# M471 register map
File version: 1.0
Registers are 32-bit, read-write, reset 0x0 unless marked. A register's access mark holds for its fields unless they carry their own. Offsets are from the block's base; [hi:lo] are bit positions; {n}, {i} and the like mark numbered series; 'fields as' and 'values as' point back to an identical list.

## SYS — SYS Register Map
Base 0x40000000
0x00 SYS_PDID ro reset 0x1647140 — Part Device Identification Number Register
  [31:0] PDID — Part Device Identification Number (Read Only). This register reflects device part number code. Software can read this register to identify which device is used. Note: After chip power-on, this bit is defined by ROMMAP2[31:0]
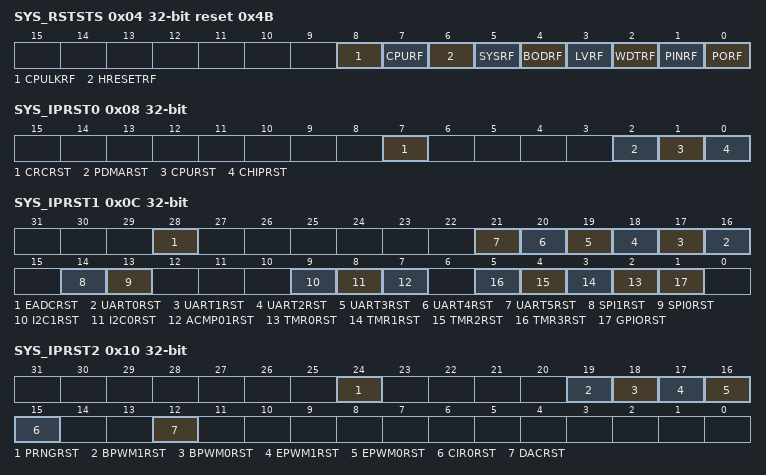
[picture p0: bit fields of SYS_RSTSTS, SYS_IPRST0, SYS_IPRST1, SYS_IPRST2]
0x04 SYS_RSTSTS reset 0x4B — System Reset Status Register
  [8] CPULKRF — CPU Lockup Reset Flag. Note 1: Write 1 to clear this bit to 0. Note 2: When CPU lockup happened under ICE is connected, this flag will set to 1 but chip will not reset.
    0=No reset from CPU lockup happened; 1=The Cortex-M4 lockup happened and chip is reset
  [7] CPURF — CPU Reset Flag. The CPU reset flag is set by hardware if software writes CPURST (SYS_IPRST0[1]) 1 to reset Cortex-M4 Core and Flash Memory Controller (FMC). Note: Write 1 to clear this bit to 0.
    0=No reset from CPU; 1=The Cortex-M4 Core and FMC are reset by software setting CPURST to 1
  [6] HRESETRF — HRESET Reset Flag. The HRESET reset flag is set by the 'Reset Signal' from the HRESET. Note: Write 1 to clear this bit to 0.
    0=No reset from HRESET; 1=Reset from HRESET
  [5] SYSRF — System Reset Flag. The system reset flag is set by the 'Reset Signal' from the Cortex-M4 Core to indicate the previous reset source. Note: Write 1 to clear this bit to 0.
    0=No reset from Cortex-M4; 1=The Cortex-M4 had issued the reset signal to reset the system by writing 1 to the bit SYSRESETREQ(AIRCR[2], Application Interrupt and Reset Control Register, address = 0xE000ED0C) in system control registers of Cortex-M4 core
  [4] BODRF — BOD Reset Flag. The BOD reset flag is set by the 'Reset Signal' from the Brown-Out Detector to indicate the previous reset source. Note: Write 1 to clear this bit to 0.
    0=No reset from BOD; 1=The BOD had issued the reset signal to reset the system
  [3] LVRF — LVR Reset Flag. The LVR reset flag is set by the 'Reset Signal' from the Low Voltage Reset Controller to indicate the previous reset source. Note: Write 1 to clear this bit to 0.
    0=No reset from LVR; 1=LVR controller had issued the reset signal to reset the system
  [2] WDTRF — WDT Reset Flag. The WDT reset flag is set by the 'Reset Signal' from the Watchdog Timer or Window Watchdog Timer to indicate the previous reset source. Note 1: Write 1 to clear this bit to 0. Note 2: Watchdog Timer register RSTF(WDT_CTL[2]) bit is set if the system has been reset by WDT time-out reset. Window Watchdog Timer register WWDTRF(WWDT_STATUS[1]) bit is set if the system has been reset by WWDT time-out reset.
    0=No reset from watchdog timer or window watchdog timer; 1=The watchdog timer or window watchdog timer had issued the reset signal to reset the system
  [1] PINRF — NRESET Pin Reset Flag. The nRESET pin reset flag is set by the 'Reset Signal' from the nRESET Pin to indicate the previous reset source. Note: Write 1 to clear this bit to 0.
    0=No reset from nRESET pin; 1=Pin nRESET had issued the reset signal to reset the system
  [0] PORF — POR Reset Flag. The POR reset flag is set by the 'Reset Signal' from the Power-on Reset (POR) Controller or bit CHIPRST (SYS_IPRST0[0]) to indicate the previous reset source. Note: Write 1 to clear this bit to 0.
    0=No reset from POR or CHIPRST; 1=Power-on Reset (POR) or CHIPRST had issued the reset signal to reset the system
0x08 SYS_IPRST0 — Peripheral Reset Control Register 0
  [7] CRCRST — CRC Calculation Controller Reset (Write Protect). Set this bit to 1 will generate a reset signal to the CRC calculation controller. User needs to set this bit to 0 to release from the reset state. Note: This bit is write protected. Refer to the SYS_REGLCTL register.
    0=CRC calculation controller normal operation; 1=CRC calculation controller reset
  [2] PDMARST — PDMA Controller Reset (Write Protect). Setting this bit to 1 will generate a reset signal to the PDMA. User needs to set this bit to 0 to release from reset state. Note: This bit is write protected. Refer to the SYS_REGLCTL register.
    0=PDMA controller normal operation; 1=PDMA controller reset
  [1] CPURST — Processor Core One-shot Reset (Write Protect). Setting this bit will only reset the processor core and Flash Memory Controller(FMC), and this bit will automatically return to 0 after the 2 clock cycles. Note: This bit is write protected. Refer to the SYS_REGLCTL register.
    0=Processor core normal operation; 1=Processor core one-shot reset
  [0] CHIPRST — Chip One-shot Reset (Write Protect). Setting this bit will reset the whole chip, including Processor core and all peripherals, and this bit will automatically return to 0 after the 2 clock cycles. The CHIPRST is same as the POR reset, all the chip controllers is reset and the chip setting from Flash are also reload. About the difference between CHIPRST and SYSRESETREQ(AIRCR[2]), please refer to section 7.2.2. Note: This bit is write protected. Refer to the SYS_REGLCTL register.
    0=Chip normal operation; 1=Chip one-shot reset
0x0C SYS_IPRST1 — Peripheral Reset Control Register 1
  [28] EADCRST — EADC Controller Reset
    0=EADC controller normal operation; 1=EADC controller reset
  [n+16] UART{n}RST (n=0..5) — UART{n} Controller Reset
    0=UART{n} controller normal operation; 1=UART{n} controller reset
  [14] SPI1RST — SPI1 Controller Reset
    0=SPI1 controller normal operation; 1=SPI1 controller reset
  [13] SPI0RST — SPI0 Controller Reset
    0=SPI0 controller normal operation; 1=SPI0 controller reset
  [9] I2C1RST — I2C1 Controller Reset
    0=I2C1 controller normal operation; 1=I2C1 controller reset
  [8] I2C0RST — I2C0 Controller Reset
    0=I2C0 controller normal operation; 1=I2C0 controller reset
  [7] ACMP01RST — Analog Comparator 0/1 Controller Reset
    0=Analog Comparator 0/1 controller normal operation; 1=Analog Comparator 0/1 controller reset
  [n+2] TMR{n}RST (n=0..3) — Timer{n} Controller Reset
    0=Timer{n} controller normal operation; 1=Timer{n} controller reset
  [1] GPIORST — GPIO Controller Reset
    0=GPIO controller normal operation; 1=GPIO controller reset
0x10 SYS_IPRST2 — Peripheral Reset Control Register 2
  [24] PRNGRST — PRNG Controller Reset
    0=PRNG controller normal operation; 1=PRNG controller reset
  [19] BPWM1RST — BPWM1 Controller Reset
    0=BPWM1 controller normal operation; 1=BPWM1 controller reset
  [18] BPWM0RST — BPWM0 Controller Reset
    0=BPWM0 controller normal operation; 1=BPWM0 controller reset
  [17] EPWM1RST — EPWM1 Controller Reset
    0=EPWM1 controller normal operation; 1=EPWM1 controller reset
  [16] EPWM0RST — EPWM0 Controller Reset
    0=EPWM0 controller normal operation; 1=EPWM0 controller reset
  [15] CIR0RST — CIR0 Controller Reset
    0=CIR0 controller normal operation; 1=CIR0 controller reset
  [12] DACRST — DAC Controller Reset
    0=DAC controller normal operation; 1=DAC controller reset
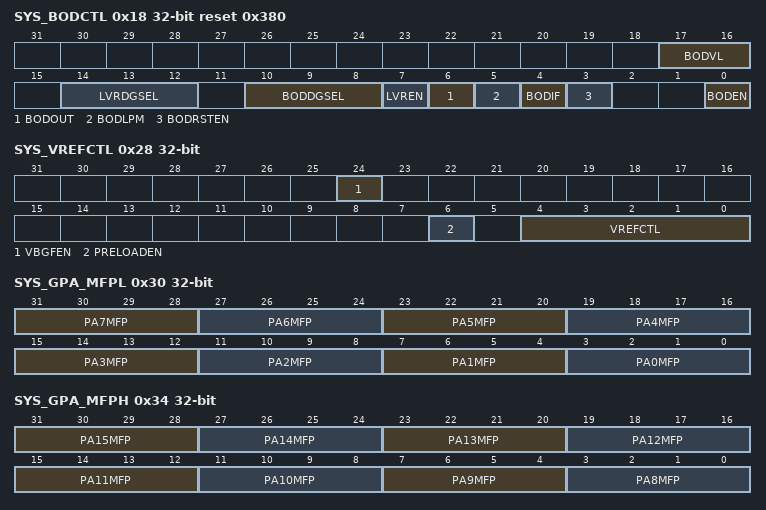
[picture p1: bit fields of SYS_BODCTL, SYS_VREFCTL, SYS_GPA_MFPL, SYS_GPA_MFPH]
0x18 SYS_BODCTL reset 0x380 (reset mask 0xFFF0FFF0) — Brown-out Detector Control Register
  [17:16] BODVL — Brown-out Detector Threshold Voltage Selection (Write Protect). The default value is set by Flash controller user configuration register CBOV (CONFIG0 [22:21]). Note: This bit is write protected. Refer to the SYS_REGLCTL register.
    0=Brown-Out Detector threshold voltage is 2.4V; 1=Brown-Out Detector threshold voltage is 2.7V; 2=Brown-Out Detector threshold voltage is 3.7V; 3=Brown-Out Detector threshold voltage is 4.4V
  [14:12] LVRDGSEL — LVR Output De-glitch Time Select (Write Protect). Note: These bits are write protected. Refer to the SYS_REGLCTL register.
    0=Without de-glitch function; 1=4 system clock (HCLK); 2=8 system clock (HCLK); 3=16 system clock (HCLK); 4=32 system clock (HCLK); 5=64 system clock (HCLK); 6=128 system clock (HCLK); 7=256 system clock (HCLK)
  [10:8] BODDGSEL — Brown-out Detector Output De-glitch Time Select (Write Protect). Note: These bits are write protected. Refer to the SYS_REGLCTL register.
    0=BOD output is sampled by RC10K clock; 1=4 system clock (HCLK); 2=8 system clock (HCLK); 3=16 system clock (HCLK); 4=32 system clock (HCLK); 5=64 system clock (HCLK); 6=128 system clock (HCLK); 7=256 system clock (HCLK)
  [7] LVREN — Low Voltage Reset Enable Bit (Write Protect). The LVR function resets the chip when the input power voltage is lower than LVR circuit setting. LVR function is enabled by default. Note 1: After enabling the bit, the LVR function will be active with 100us delay for LVR output stable (default). Note 2: This bit is write protected. Refer to the SYS_REGLCTL register.
    0=Low Voltage Reset function Disabled; 1=Low Voltage Reset function Enabled
  [6] BODOUT — Brown-out Detector Output Status. It means the detected voltage is lower than BODVL setting. If the BODEN is 0, BOD function disabled, this bit always responds 0.
    0=Brown-out Detector output status is 0; 1=Brown-out Detector output status is 1
  [5] BODLPM — Brown-out Detector Low Power Mode (Write Protect). Note 1: The BOD consumes about 100uA in normal mode, the low power mode can reduce the current to about 1/10 but slow the BOD response. Note 2: This bit is write protected. Refer to the SYS_REGLCTL register. Note 3:BOD enable stable time is 50us, period enable time need larger than it
    0=BOD operate in normal mode (default); 1=BOD Low Power mode Enabled
  [4] BODIF — Brown-out Detector Interrupt Flag. Note: Write 1 to clear this bit to 0.
    0=Brown-out Detector does not detect any voltage draft at VDD down through or up through the voltage of BODVL setting; 1=When Brown-out Detector detects the VDD is dropped down through the voltage of BODVL setting or the VDD is raised up through the voltage of BODVL setting, this bit is set to 1 and the brown-out interrupt is requested if brown-out interrupt is enabled
  [3] BODRSTEN — Brown-out Reset Enable Bit (Write Protect). The default value is set by Flash controller user configuration register CBORST(CONFIG0[20]) bit. Note 1: While the Brown-out Detector function is enabled (BODEN high) and BOD reset function is enabled (BODRSTEN high), BOD will assert a signal to reset chip when the detected voltage is lower than the threshold (BODOUT high). While the BOD function is enabled (BODEN high) and BOD interrupt function is enabled (BODRSTEN low), BOD will assert an interrupt if BODOUT is high. BOD interrupt will be kept till to the BODEN is set to 0. BOD interrupt can be blocked by disabling the NVIC BOD interrupt or disabling BOD function (set BODEN low). Note 2: This bit is write protected. Refer to the SYS_REGLCTL register.
    0=Brown-out 'INTERRUPT' function Enabled; 1=Brown-out 'RESET' function Enabled
  [0] BODEN — Brown-out Detector Enable Bit (Write Protect). The default value is set by Flash controller user configuration register CBODEN (CONFIG0 [19]). Note: This bit is write protected. Refer to the SYS_REGLCTL register.
    0=Brown-out Detector function Disabled; 1=Brown-out Detector function Enabled
0x1C SYS_IVSCTL — Internal Voltage Source Control Register
  [0] VTEMPEN — Temperature Sensor Enable Bit. This bit is used to enable/disable temperature sensor function.
    0=Temperature sensor function Disabled (default); 1=Temperature sensor function Enabled
0x28 SYS_VREFCTL — VREF Control Register
  [24] VBGFEN wo — Chip Internal Voltage Band-gap Force Enable Bit(Write Only). Note: If user want to read the value of this bit, please read bit[25].
    0=Chip internal voltage band-gap controlled by ADC/ACMP if source selected; 1=Chip internal voltage band-gap force enable
  [6] PRELOADEN — Pre-load Function Enable Bit (Write Protect). This bit should be enabled and keep during Tstable when VREFCTL(SYS_VREFCTL[4:0]) change setting(except set to 00000). Tstable depends on different situations has different requirement, please refer to Datasheet. Note 1: This bit is write protected. Refer to the SYS_REGLCTL register.
    0=VREF Pre-load function Disabled. (Default); 1=VREF Pre-load function Enabled
  [4:0] VREFCTL — VREF Control Bits (Write Protect). Note: This bit is write protected. Refer to the SYS_REGLCTL register.
    0=VREF is from external pin; 2=VREF is from internal reference voltage 2.048V; 6=VREF is from internal reference voltage 2.56V; 10=VREF is from internal reference voltage 3.072V; 14=VREF is from internal reference voltage 4.096V
0x30 SYS_GPA_MFPL — GPIOA Low Byte Multiple Function Control Register
  [31:28] PA7MFP — PA.7 Multi-function Pin Selection
  [27:24] PA6MFP — PA.6 Multi-function Pin Selection
  [23:20] PA5MFP — PA.5 Multi-function Pin Selection
  [19:16] PA4MFP — PA.4 Multi-function Pin Selection
  [15:12] PA3MFP — PA.3 Multi-function Pin Selection
  [11:8] PA2MFP — PA.2 Multi-function Pin Selection
  [7:4] PA1MFP — PA.1 Multi-function Pin Selection
  [3:0] PA0MFP — PA.0 Multi-function Pin Selection
0x34 SYS_GPA_MFPH — GPIOA High Byte Multiple Function Control Register
  [31:28] PA15MFP — PA.15 Multi-function Pin Selection
  [27:24] PA14MFP — PA.14 Multi-function Pin Selection
  [23:20] PA13MFP — PA.13 Multi-function Pin Selection
  [19:16] PA12MFP — PA.12 Multi-function Pin Selection
  [15:12] PA11MFP — PA.11 Multi-function Pin Selection
  [11:8] PA10MFP — PA.10 Multi-function Pin Selection
  [7:4] PA9MFP — PA.9 Multi-function Pin Selection
  [3:0] PA8MFP — PA.8 Multi-function Pin Selection
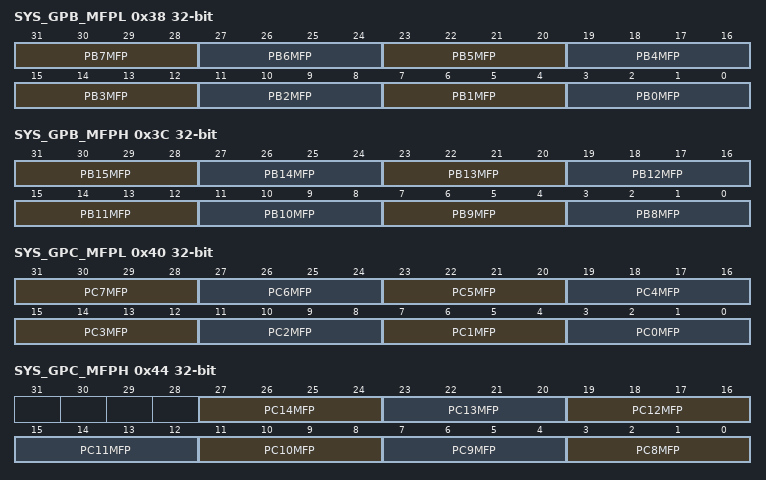
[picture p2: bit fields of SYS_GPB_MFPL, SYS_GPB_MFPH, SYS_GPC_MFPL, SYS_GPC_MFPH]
0x38 SYS_GPB_MFPL — GPIOB Low Byte Multiple Function Control Register
  [31:28] PB7MFP — PB.7 Multi-function Pin Selection
  [27:24] PB6MFP — PB.6 Multi-function Pin Selection
  [23:20] PB5MFP — PB.5 Multi-function Pin Selection
  [19:16] PB4MFP — PB.4 Multi-function Pin Selection
  [15:12] PB3MFP — PB.3 Multi-function Pin Selection
  [11:8] PB2MFP — PB.2 Multi-function Pin Selection
  [7:4] PB1MFP — PB.1 Multi-function Pin Selection
  [3:0] PB0MFP — PB.0 Multi-function Pin Selection
0x3C SYS_GPB_MFPH — GPIOB High Byte Multiple Function Control Register
  [31:28] PB15MFP — PB.15 Multi-function Pin Selection
  [27:24] PB14MFP — PB.14 Multi-function Pin Selection
  [23:20] PB13MFP — PB.13 Multi-function Pin Selection
  [19:16] PB12MFP — PB.12 Multi-function Pin Selection
  [15:12] PB11MFP — PB.11 Multi-function Pin Selection
  [11:8] PB10MFP — PB.10 Multi-function Pin Selection
  [7:4] PB9MFP — PB.9 Multi-function Pin Selection
  [3:0] PB8MFP — PB.8 Multi-function Pin Selection
0x40 SYS_GPC_MFPL — GPIOC Low Byte Multiple Function Control Register
  [31:28] PC7MFP — PC.7 Multi-function Pin Selection
  [27:24] PC6MFP — PC.6 Multi-function Pin Selection
  [23:20] PC5MFP — PC.5 Multi-function Pin Selection
  [19:16] PC4MFP — PC.4 Multi-function Pin Selection
  [15:12] PC3MFP — PC.3 Multi-function Pin Selection
  [11:8] PC2MFP — PC.2 Multi-function Pin Selection
  [7:4] PC1MFP — PC.1 Multi-function Pin Selection
  [3:0] PC0MFP — PC.0 Multi-function Pin Selection
0x44 SYS_GPC_MFPH — GPIOC High Byte Multiple Function Control Register
  [27:24] PC14MFP — PC.14 Multi-function Pin Selection
  [23:20] PC13MFP — PC.13 Multi-function Pin Selection
  [19:16] PC12MFP — PC.12 Multi-function Pin Selection
  [15:12] PC11MFP — PC.11 Multi-function Pin Selection
  [11:8] PC10MFP — PC.10 Multi-function Pin Selection
  [7:4] PC9MFP — PC.9 Multi-function Pin Selection
  [3:0] PC8MFP — PC.8 Multi-function Pin Selection
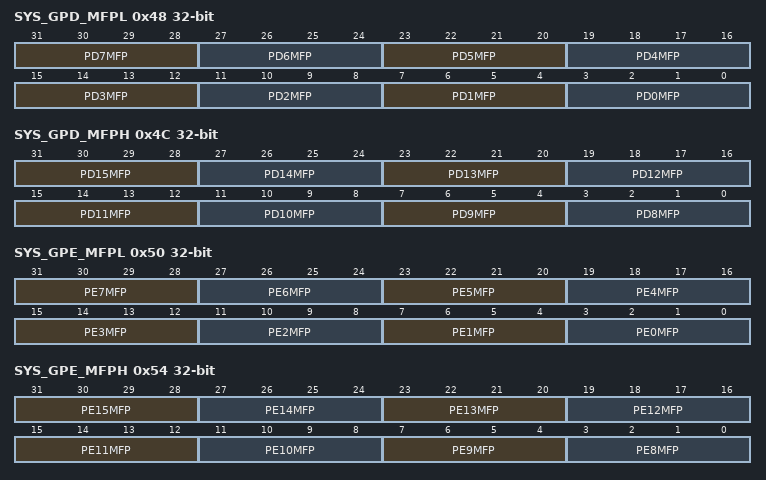
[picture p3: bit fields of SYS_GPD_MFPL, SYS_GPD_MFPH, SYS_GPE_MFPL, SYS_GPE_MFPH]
0x48 SYS_GPD_MFPL — GPIOD Low Byte Multiple Function Control Register
  [31:28] PD7MFP — PD.7 Multi-function Pin Selection
  [27:24] PD6MFP — PD.6 Multi-function Pin Selection
  [23:20] PD5MFP — PD.5 Multi-function Pin Selection
  [19:16] PD4MFP — PD.4 Multi-function Pin Selection
  [15:12] PD3MFP — PD.3 Multi-function Pin Selection
  [11:8] PD2MFP — PD.2 Multi-function Pin Selection
  [7:4] PD1MFP — PD.1 Multi-function Pin Selection
  [3:0] PD0MFP — PD.0 Multi-function Pin Selection
0x4C SYS_GPD_MFPH — GPIOD High Byte Multiple Function Control Register
  [31:28] PD15MFP — PD.15 Multi-function Pin Selection
  [27:24] PD14MFP — PD.14 Multi-function Pin Selection
  [23:20] PD13MFP — PD.13 Multi-function Pin Selection
  [19:16] PD12MFP — PD.12 Multi-function Pin Selection
  [15:12] PD11MFP — PD.11 Multi-function Pin Selection
  [11:8] PD10MFP — PD.10 Multi-function Pin Selection
  [7:4] PD9MFP — PD.9 Multi-function Pin Selection
  [3:0] PD8MFP — PD.8 Multi-function Pin Selection
0x50 SYS_GPE_MFPL — GPIOE Low Byte Multiple Function Control Register
  [31:28] PE7MFP — PE.7 Multi-function Pin Selection
  [27:24] PE6MFP — PE.6 Multi-function Pin Selection
  [23:20] PE5MFP — PE.5 Multi-function Pin Selection
  [19:16] PE4MFP — PE.4 Multi-function Pin Selection
  [15:12] PE3MFP — PE.3 Multi-function Pin Selection
  [11:8] PE2MFP — PE.2 Multi-function Pin Selection
  [7:4] PE1MFP — PE.1 Multi-function Pin Selection
  [3:0] PE0MFP — PE.0 Multi-function Pin Selection
0x54 SYS_GPE_MFPH — GPIOE High Byte Multiple Function Control Register
  [31:28] PE15MFP — PE.15 Multi-function Pin Selection
  [27:24] PE14MFP — PE.14 Multi-function Pin Selection
  [23:20] PE13MFP — PE.13 Multi-function Pin Selection
  [19:16] PE12MFP — PE.12 Multi-function Pin Selection
  [15:12] PE11MFP — PE.11 Multi-function Pin Selection
  [11:8] PE10MFP — PE.10 Multi-function Pin Selection
  [7:4] PE9MFP — PE.9 Multi-function Pin Selection
  [3:0] PE8MFP — PE.8 Multi-function Pin Selection
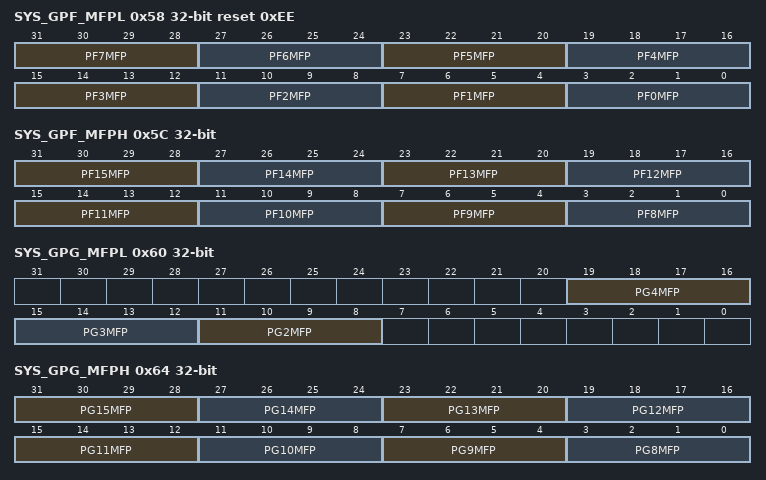
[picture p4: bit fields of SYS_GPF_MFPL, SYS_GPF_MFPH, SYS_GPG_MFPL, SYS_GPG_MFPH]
0x58 SYS_GPF_MFPL reset 0xEE — GPIOF Low Byte Multiple Function Control Register
  [31:28] PF7MFP — PF.7 Multi-function Pin Selection
  [27:24] PF6MFP — PF.6 Multi-function Pin Selection
  [23:20] PF5MFP — PF.5 Multi-function Pin Selection
  [19:16] PF4MFP — PF.4 Multi-function Pin Selection
  [15:12] PF3MFP — PF.3 Multi-function Pin Selection
  [11:8] PF2MFP — PF.2 Multi-function Pin Selection
  [7:4] PF1MFP — PF.1 Multi-function Pin Selection
  [3:0] PF0MFP — PF.0 Multi-function Pin Selection
0x5C SYS_GPF_MFPH — GPIOF High Byte Multiple Function Control Register
  [31:28] PF15MFP — PF.15 Multi-function Pin Selection
  [27:24] PF14MFP — PF.14 Multi-function Pin Selection
  [23:20] PF13MFP — PF.13 Multi-function Pin Selection
  [19:16] PF12MFP — PF.12 Multi-function Pin Selection
  [15:12] PF11MFP — PF.11 Multi-function Pin Selection
  [11:8] PF10MFP — PF.10 Multi-function Pin Selection
  [7:4] PF9MFP — PF.9 Multi-function Pin Selection
  [3:0] PF8MFP — PF.8 Multi-function Pin Selection
0x60 SYS_GPG_MFPL — GPIOG Low Byte Multiple Function Control Register
  [19:16] PG4MFP — PG.4 Multi-function Pin Selection
  [15:12] PG3MFP — PG.3 Multi-function Pin Selection
  [11:8] PG2MFP — PG.2 Multi-function Pin Selection
0x64 SYS_GPG_MFPH — GPIOG High Byte Multiple Function Control Register
  [31:28] PG15MFP — PG.15 Multi-function Pin Selection
  [27:24] PG14MFP — PG.14 Multi-function Pin Selection
  [23:20] PG13MFP — PG.13 Multi-function Pin Selection
  [19:16] PG12MFP — PG.12 Multi-function Pin Selection
  [15:12] PG11MFP — PG.11 Multi-function Pin Selection
  [11:8] PG10MFP — PG.10 Multi-function Pin Selection
  [7:4] PG9MFP — PG.9 Multi-function Pin Selection
  [3:0] PG8MFP — PG.8 Multi-function Pin Selection
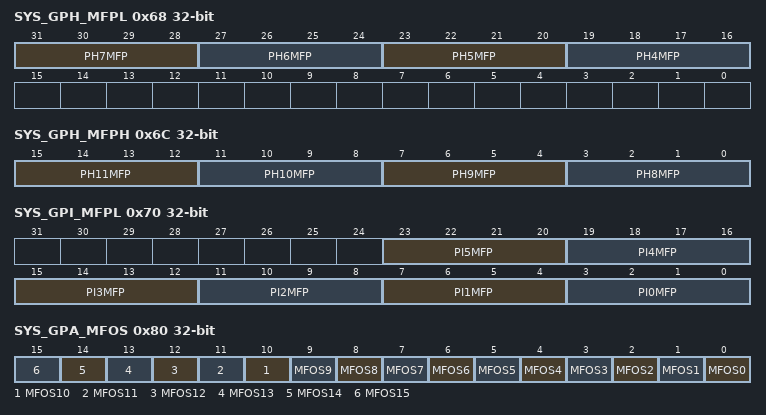
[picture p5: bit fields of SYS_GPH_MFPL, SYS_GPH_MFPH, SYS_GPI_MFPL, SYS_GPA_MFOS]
0x68 SYS_GPH_MFPL — GPIOH Low Byte Multiple Function Control Register
  [31:28] PH7MFP — PH.7 Multi-function Pin Selection
  [27:24] PH6MFP — PH.6 Multi-function Pin Selection
  [23:20] PH5MFP — PH.5 Multi-function Pin Selection
  [19:16] PH4MFP — PH.4 Multi-function Pin Selection
0x6C SYS_GPH_MFPH — GPIOH High Byte Multiple Function Control Register
  [15:12] PH11MFP — PH.11 Multi-function Pin Selection
  [11:8] PH10MFP — PH.10 Multi-function Pin Selection
  [7:4] PH9MFP — PH.9 Multi-function Pin Selection
  [3:0] PH8MFP — PH.8 Multi-function Pin Selection
0x70 SYS_GPI_MFPL — GPIOI Low Byte Multiple Function Control Register
  [23:20] PI5MFP — PI.5 Multi-function Pin Selection
  [19:16] PI4MFP — PI.4 Multi-function Pin Selection
  [15:12] PI3MFP — PI.3 Multi-function Pin Selection
  [11:8] PI2MFP — PI.2 Multi-function Pin Selection
  [7:4] PI1MFP — PI.1 Multi-function Pin Selection
  [3:0] PI0MFP — PI.0 Multi-function Pin Selection
0x80 SYS_GPA_MFOS — GPIOA Multiple Function Output Select Register
  [all] fields
    0=Multiple function pin output mode type is Push-pull mode; 1=Multiple function pin output mode type is Open-drain mode
  [n] MFOS{n} (n=0..15) — GPIOA-h Pin[n] Multiple Function Pin Output Mode Select. This bit used to select multiple function pin output mode type for Px.n pin. The PC15/PG0/PG1/PG5/PG6/PG7/PG8/PH0/PH1/PH2/PH3/PH12/PH13/PH14/PH15 pins are not available.
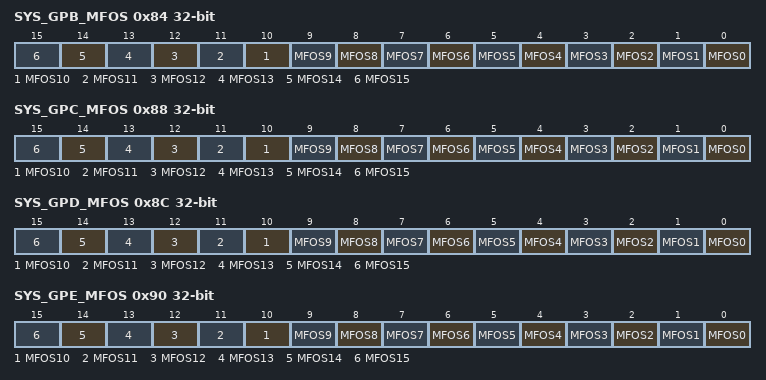
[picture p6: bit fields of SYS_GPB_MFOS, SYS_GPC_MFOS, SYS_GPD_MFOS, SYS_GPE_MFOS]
0x84 SYS_GPB_MFOS — GPIOB Multiple Function Output Select Register
  fields as SYS_GPA_MFOS
0x88 SYS_GPC_MFOS — GPIOC Multiple Function Output Select Register
  fields as SYS_GPA_MFOS
0x8C SYS_GPD_MFOS — GPIOD Multiple Function Output Select Register
  fields as SYS_GPA_MFOS
0x90 SYS_GPE_MFOS — GPIOE Multiple Function Output Select Register
  fields as SYS_GPA_MFOS
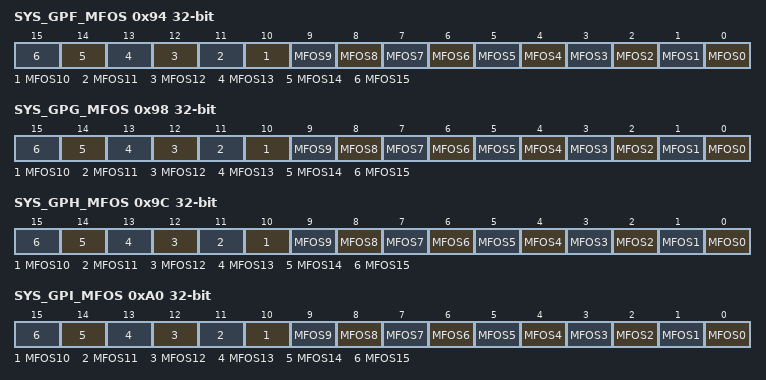
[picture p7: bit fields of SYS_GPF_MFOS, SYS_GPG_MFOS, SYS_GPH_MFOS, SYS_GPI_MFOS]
0x94 SYS_GPF_MFOS — GPIOF Multiple Function Output Select Register
  fields as SYS_GPA_MFOS
0x98 SYS_GPG_MFOS — GPIOG Multiple Function Output Select Register
  fields as SYS_GPA_MFOS
0x9C SYS_GPH_MFOS — GPIOH Multiple Function Output Select Register
  fields as SYS_GPA_MFOS
0xA0 SYS_GPI_MFOS — GPIOI Multiple Function Output Select Register
  fields as SYS_GPA_MFOS
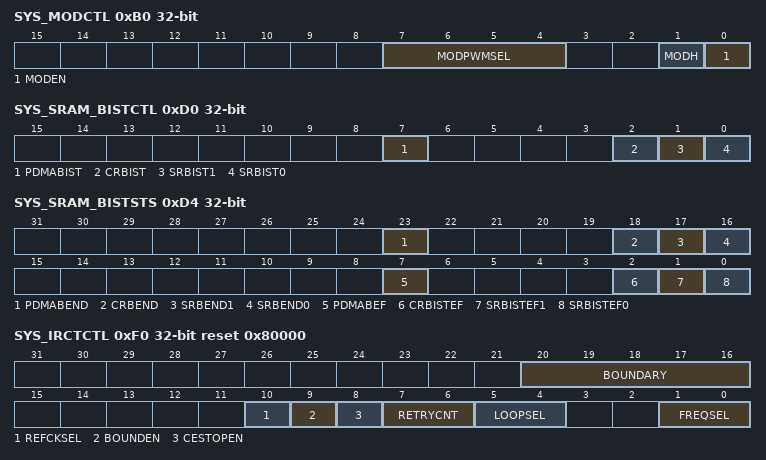
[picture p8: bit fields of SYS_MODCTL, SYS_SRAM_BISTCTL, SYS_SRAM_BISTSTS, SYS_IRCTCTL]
0xB0 SYS_MODCTL — Modulation Control Register
  [7:4] MODPWMSEL — EPWM0 Channel Select for Modulation. Select the EPWM0 channel to modulate with the UART0_TXD. 0000: EPWM0 Channel 0 modulate with UART0_TXD. 0001: EPWM0 Channel 1 modulate with UART0_TXD. 0010: EPWM0 Channel 2 modulate with UART0_TXD. 0011: EPWM0 Channel 3 modulete with UART0_TXD. 0100: EPWM0 Channel 4 modulete with UART0_TXD. 0101: EPWM0 Channel 5 modulete with UART0_TXD. 0110: Reserved. 0111: Reserved. 1000: Reserved. 1001: Reserved. 1010: Reserved. 1011: Reserved. 1100: Reserved. 1101: Reserved. 1110: Reserved. 1111: Reserved. Note: This bis is valid while MODEN (SYS_MODCTL[0]) is set to 1.
  [1] MODH — Modulation at Data High. Select modulation pulse(EPWM0) at high or low of UART0_TXD. 0: Modulation pulse at UART0_TXD low. 1: Modulation pulse at UART0_TXD high.
  [0] MODEN — Modulation Function Enable Bit. This bit enables modulation funcion by modulating with EPWM0 channel output and UART0(UART0_TXD) output.
    0=Modulation Function Disabled; 1=Modulation Function Enabled
0xC0 SYS_SRAM_INTCTL — System SRAM Interrupt Enable Control Register
  [0] PERRIEN — SRAM Parity Check Error Interrupt Enable Bit
    0=SRAM parity check error interrupt Disabled; 1=SRAM parity check error interrupt Enabled
0xC4 SYS_SRAM_STATUS — System SRAM Parity Error Status Register
  [0] PERRIF — SRAM Parity Check Error Flag. This bit indicates the System SRAM parity error occurred. Write 1 to clear this to 0.
    0=No System SRAM parity error; 1=System SRAM parity error occur
0xC8 SYS_SRAM_ERRADDR ro — System SRAM Parity Check Error Address Register
  [31:0] ERRADDR — System SRAM Parity Error Address. This register shows system SRAM parity error byte address.
0xD0 SYS_SRAM_BISTCTL — System SRAM BIST Test Control Register
  [7] PDMABIST — PDMA BIST Enable Bit (Write Protect). This bit enables BIST test for PDMA RAM. Note: This bit is write protected. Refer to the SYS_REGLCTL register.
    0=system PDMA BIST Disabled; 1=system PDMA BIST Enabled
  [2] CRBIST — CACHE BIST Enable Bit (Write Protect). This bit enables BIST test for CACHE RAM. Note: This bit is write protected. Refer to the SYS_REGLCTL register.
    0=system CACHE BIST Disabled; 1=system CACHE BIST Enabled
  [1] SRBIST1 — SRAM Bank1 BIST Enable Bit (Write Protect). This bit enables BIST test for SRAM bank1. Note: This bit is write protected. Refer to the SYS_REGLCTL register.
    0=system SRAM bank1 BIST Disabled; 1=system SRAM bank1 BIST Enabled
  [0] SRBIST0 — SRAM Bank0 BIST Enable Bit (Write Protect). This bit enables BIST test for SRAM bank0. Note: This bit is write protected. Refer to the SYS_REGLCTL register.
    0=system SRAM bank0 BIST Disabled; 1=system SRAM bank0 BIST Enabled
0xD4 SYS_SRAM_BISTSTS ro (reset mask 0xFF00FF00) — System SRAM BIST Test Status Register
  [23] PDMABEND — PDMA SRAM BIST Test Finish
    0=PDMA SRAM BIST is active; 1=PDMA SRAM BIST test finish
  [18] CRBEND — CACHE SRAM BIST Test Finish
    0=System CACHE RAM BIST is active; 1=System CACHE RAM BIST test finish
  [17] SRBEND1 — 2nd SRAM BIST Test Finish
    0=2nd system SRAM BIST is active; 1=2nd system SRAM BIST finish
  [16] SRBEND0 — 1st SRAM BIST Test Finish
    0=1st system SRAM BIST active; 1=1st system SRAM BIST finish
  [7] PDMABEF — PDMA SRAM BIST Fail Flag
    0=PDMA SRAM BIST test pass; 1=PDMA SRAM BIST test fail
  [2] CRBISTEF — CACHE SRAM BIST Fail Flag
    0=System CACHE RAM BIST test pass; 1=System CACHE RAM BIST test fail
  [1] SRBISTEF1 — 2nd System SRAM BIST Fail Flag
    0=2nd system SRAM BIST test pass; 1=2nd system SRAM BIST test fail
  [0] SRBISTEF0 — 1st System SRAM BIST Fail Flag
    0=1st system SRAM BIST test pass; 1=1st system SRAM BIST test fail
0xF0 SYS_IRCTCTL reset 0x80000 — HIRC Trim Control Register
  [20:16] BOUNDARY — Boundary Selection. Fill the boundary range from 0x1 to 0x31, 0x0 is reserved. This field shows the update value range. If the difference between the current trim value and the new update trim value is smaller than BOUNDARY value, then the trim value will be update to RC or it will keep the current trim value. Note 1: When the RC clock shift over 0.25 percent due to temperature condition in lock state, rc_trim circuit will increase or decrease at least 2 to trim value. Note 2: Only when the difference of the current frequency count and the target frequency count is smaller than 0.25 percent in unlock state, rc_trim circuit will increase or decrease 1 to trim value. Note: This field is effective only when the BOUNDEN(SYS_IRCTCTL[9]) is enabled.
  [10] REFCKSEL — Reference Clock Selection. Note: The HIRC trim reference clock is 20 kHz in test mode.
    0=HIRC trim reference clock is from LXT (32.768 kHz)
  [9] BOUNDEN — Boundary Enable Bit
    0=Boundary function Disabled; 1=Boundary function Enabled
  [8] CESTOPEN — Clock Error Stop Enable Bit
    0=The trim operation keeps going if clock is inaccurate; 1=The trim operation is stopped if clock is inaccurate
  [7:6] RETRYCNT — Trim Value Update Limitation Count. This field defines that how many times the auto trim circuit will try to update the HIRC trim value before the frequency of HIRC locked. Once the HIRC is locked, the internal trim value update counter will be reset. If the trim value update counter reaches this limitation value and the frequency of HIRC is still not locked, the auto trim operation will be disabled and FREQSEL will be cleared to 00.
    0=Trim retry count limitation is 64 loops; 1=Trim retry count limitation is 128 loops; 2=Trim retry count limitation is 256 loops; 3=Trim retry count limitation is 512 loops
  [5:4] LOOPSEL — Trim Calculation Loop Selection. This field defines that trim value calculation is based on how many reference clocks. Note: For example, if LOOPSEL is set as 00, auto trim circuit will calculate trim value based on the average frequency difference in 4 clocks of reference clock.
    0=Trim value calculation is based on average difference in 4 clocks of reference clock; 1=Trim value calculation is based on average difference in 8 clocks of reference clock; 2=Trim value calculation is based on average difference in 16 clocks of reference clock; 3=Trim value calculation is based on average difference in 32 clocks of reference clock
  [1:0] FREQSEL — Trim Frequency Selection. This field indicates the target frequency of 48 MHz internal high speed RC oscillator (HIRC) auto trim. During auto trim operation, if clock error detected with CESTOPEN is set to 1 or trim retry limitation count reached, this field will be cleared to 00 automatically. Note: Only when the LXT and HIRC is stable, then the FREQSEL setting will be load to HIRC auto trim circuit.
    0=Disable HIRC auto trim function; 1=Enable HIRC auto trim function and trim HIRC to 48 MHz
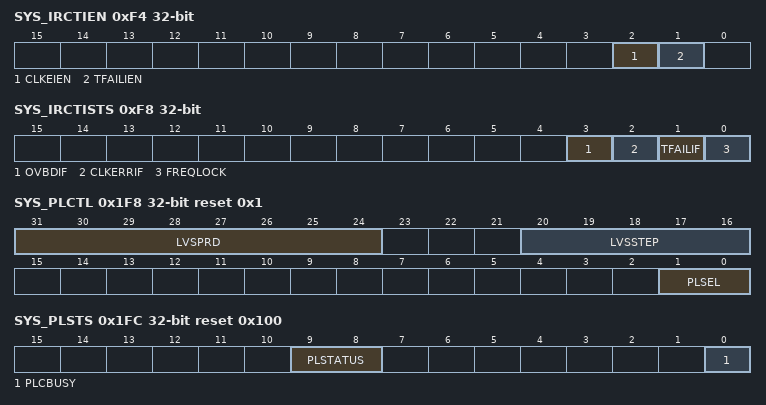
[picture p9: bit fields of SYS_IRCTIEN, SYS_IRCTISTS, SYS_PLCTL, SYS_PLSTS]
0xF4 SYS_IRCTIEN — HIRC Trim Interrupt Enable Register
  [2] CLKEIEN — Clock Error Interrupt Enable Bit. This bit controls if CPU would get an interrupt while clock is inaccurate during auto trim operation. If this bit is set to1, and CLKERRIF(SYS_IRCTISTS[2]) is set during auto trim operation, an interrupt will be triggered to notify the clock frequency is inaccurate.
    0=Disable CLKERRIF(SYS_IRCTISTS[2]) status to trigger an interrupt to CPU; 1=Enable CLKERRIF(SYS_IRCTISTS[2]) status to trigger an interrupt to CPU
  [1] TFAILIEN — Trim Failure Interrupt Enable Bit. This bit controls if an interrupt will be triggered while HIRC trim value update limitation count reached and HIRC frequency still not locked on target frequency set by FREQSEL(SYS_IRCTCTL[1:0]). If this bit is high and TFAILIF(SYS_IRCTISTS[1]) is set during auto trim operation, an interrupt will be triggered to notify that HIRC trim value update limitation count was reached.
    0=Disable TFAILIF(SYS_IRCTISTS[1]) status to trigger an interrupt to CPU; 1=Enable TFAILIF(SYS_IRCTISTS[1]) status to trigger an interrupt to CPU
0xF8 SYS_IRCTISTS — HIRC Trim Interrupt Status Register
  [3] OVBDIF — Over Boundary Status. When the over boundary function is set, if there occurs the over boundary condition, this flag will be set. Note 1: Write 1 to clear this flag.
    0=Over boundary coundition did not occur; 1=Over boundary coundition occurred
  [2] CLKERRIF — Clock Error Interrupt Status. When the frequency of 32.768 kHz external low speed crystal oscillator (LXT) or 48 MHz internal high speed RC oscillator (HIRC) is shift larger to unreasonable value, this bit will be set and to be an indicate that clock frequency is inaccurate. Once this bit is set to 1, the auto trim operation stopped and FREQSEL(SYS_IRCTCL[1:0]) will be cleared to 00 by hardware automatically if CESTOPEN(SYS_IRCTCTL[8]) is set to 1. If this bit is set and CLKEIEN(SYS_IRCTIEN[2]) is high, an interrupt will be triggered to notify the clock frequency is inaccurate. Write 1 to clear this to 0.
    0=Clock frequency is accurate; 1=Clock frequency is inaccurate
  [1] TFAILIF — Trim Failure Interrupt Status. This bit indicates that HIRC trim value update limitation count is reached and the HIRC clock frequency is still not locked. Once this bit is set, the auto trim operation stopped and FREQSEL(SYS_IRCTCTL[1:0]) will be cleared to 00 by hardware automatically. If this bit is set and TFAILIEN(SYS_IRCTIEN[1]) is high, an interrupt will be triggered to notify that HIRC trim value update limitation count was reached. Write 1 to clear this to 0.
    0=Trim value update limitation count is not reached; 1=Trim value update limitation count is reached and HIRC frequency is still not locked
  [0] FREQLOCK — HIRC Frequency Lock Status. This bit indicates the HIRC frequency is locked. This is a status bit and does not trigger any interrupt. Write 1 to clear this to 0. This bit will be set automatically, if the frequency is locked and the RC_TRIM is enabled.
    0=The internal high-speed oscillator frequency is not locked at 48 MHz yet; 1=The internal high-speed oscillator frequency is locked at 48 MHz
0x100 SYS_REGLCTL — Register Lock Control Register
  [7:0] REGLCTL — Register Lock Control Code (Write Only). Some registers have write-protection function. Writing these registers have to disable the protected function by writing the sequence value '59h', '16h', '88h' to this field. After this sequence is completed, the REGLCTL bit will be set to 1 and write-protection registers can be normal write. . REGLCTL[0]. Register Lock Control Disable Index (Read Only)
    0=Write-protection Enabled for writing protected registers. Any write to the protected register is ignored; 1=Write-protection Disabled for writing protected registers
0x1EC SYS_PORDISAN — Analog POR Disable Control Register
  [15:0] POROFFAN — Power-on Reset Enable Bit (Write Protect). After powered on, user can turn off internal analog POR circuit to save power by writing 0x5AA5 to this field. The analog POR circuit will be active again when this field is set to another value or chip is reset by other reset source, including: nRESET, Watchdog, LVR reset, BOD reset, ICE reset command and the software-chip reset function. Note: This bit is write protected. Refer to the SYS_REGLCTL register.
0x1F8 SYS_PLCTL reset 0x1 — Power Level Control Register
  [31:24] LVSPRD — LDO Voltage Scaling Period(Write Protect). The LVSPRD value is the period of each LDO voltage rising step.
  [20:16] LVSSTEP — LDO Voltage Scaling Step(Write Protect). The LVSSTEP value is LDO voltage rising step.
  [1:0] PLSEL — Power Level Select(Write Protect). These bits indicate the status of power level. Note: Refer to section 6.2.5 for Power Modes and Power Level Transition.
    0=Power level is PL0. [Internal note: core voltage is 1.9V]; 1=Power level is PL1. [Internal note: core voltage is 1.8V]; 2=Power level is PL2. [Internal note: core voltage is 1.7V]
0x1FC SYS_PLSTS ro reset 0x100 — Power Level Status Register
  [9:8] PLSTATUS — Power Level Status (Read Only). This bit indicates the status of power level.
    0=Power level is PL0. [Internal note: core voltage is 1.9V]; 1=Power level is PL1. [Internal note: core voltage is 1.8V]
  [0] PLCBUSY — Power Level Change Busy Bit (Read Only). This bit is set by hardware when power level is changing. After power level change is completed, this bit will be cleared automatically by hardware.
    0=Core voltage change is completed; 1=Core voltage change is ongoing
0x400 SYS_AHBMCTL reset 0x1 — AHB Bus Matrix Priority Control Register
  [0] INTACTEN — Highest AHB Bus Priority of Cortex-M4 Core Enable Bit (Write Protect). Enable Cortex-M4 Core With Highest AHB Bus Priority In AHB Bus Matrix. Note: This bit is write protected. Refer to the SYS_REGLCTL register.
    0=Round-robin mode; 1=Cortex-M4 CPU with highest bus priority when interrupt occurred
